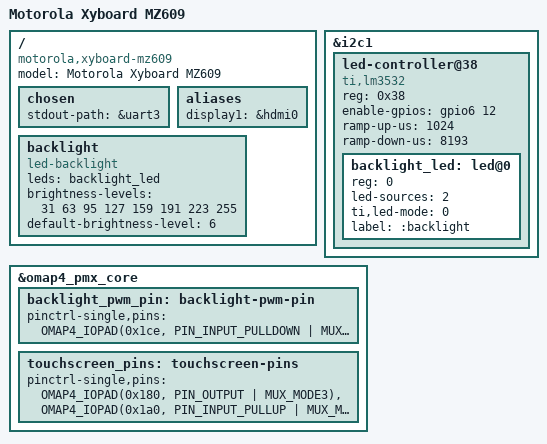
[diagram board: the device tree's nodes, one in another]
// SPDX-License-Identifier: GPL-2.0-only
/dts-v1/;

#include "motorola-mapphone-mz607-mz617.dtsi"

/ {
	model = "Motorola Xyboard MZ609";
	compatible = "motorola,xyboard-mz609", "ti,omap4430", "ti,omap4";

	chosen {
		stdout-path = &uart3;
	};

	aliases {
		display1 = &hdmi0;
	};

	backlight: backlight {
		compatible = "led-backlight";

		leds = <&backlight_led>;
		brightness-levels = <31 63 95 127 159 191 223 255>;
		default-brightness-level = <6>;
	};
};

&i2c1 {
	led-controller@38 {
		compatible = "ti,lm3532";
		#address-cells = <1>;
		#size-cells = <0>;
		reg = <0x38>;

		enable-gpios = <&gpio6 12 GPIO_ACTIVE_HIGH>;

		ramp-up-us = <1024>;
		ramp-down-us = <8193>;

		backlight_led: led@0 {
			reg = <0>;
			led-sources = <2>;
			ti,led-mode = <0>;
			label = ":backlight";
		};
	};
};
&omap4_pmx_core {
	/*
	 * 0x4a1001ce dpm_emu16.safe_mode (gpio_27) ab2, dmtimer8_pwm_evt not in
	 * use and gpio_27 pin is kept low as per lp8550 documentation.
	 */
	backlight_pwm_pin: backlight-pwm-pin {
		pinctrl-single,pins = <OMAP4_IOPAD(0x1ce, PIN_INPUT_PULLDOWN | MUX_MODE7)>;
	};

	touchscreen_pins: touchscreen-pins {
		pinctrl-single,pins =
			<OMAP4_IOPAD(0x180, PIN_OUTPUT | MUX_MODE3)>,
			<OMAP4_IOPAD(0x1a0, PIN_INPUT_PULLUP | MUX_MODE3)>;
	};
};
